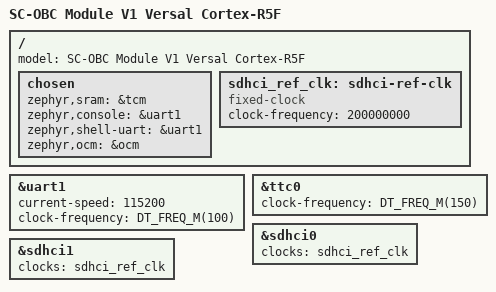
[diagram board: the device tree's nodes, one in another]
/*
 * Copyright (c) 2025 Space Cubics Inc.
 *
 * SPDX-License-Identifier: Apache-2.0
 */

/dts-v1/;
#include <arm/xilinx/versal_rpu.dtsi>
#include <freq.h>

/ {
	model = "SC-OBC Module V1 Versal Cortex-R5F";

	chosen {
		zephyr,sram = &tcm;
		zephyr,console = &uart1;
		zephyr,shell-uart = &uart1;
		zephyr,ocm = &ocm;
	};

	sdhci_ref_clk: sdhci-ref-clk {
		compatible = "fixed-clock";
		clock-frequency = <200000000>;
		#clock-cells = <0>;
	};
};

&uart1 {
	status = "okay";
	current-speed = <115200>;
	clock-frequency = <DT_FREQ_M(100)>;
};

&ttc0 {
	status = "okay";
	clock-frequency = <DT_FREQ_M(150)>;
};

&sdhci0 {
	status = "okay";
	clocks = <&sdhci_ref_clk>;
};

&sdhci1 {
	status = "okay";
	clocks = <&sdhci_ref_clk>;
};
